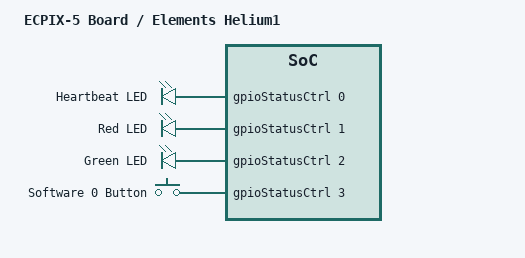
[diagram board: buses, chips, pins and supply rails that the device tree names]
/dts-v1/;
#include <elements/helium1.dtsi>

/ {
	model = "ECPIX-5 Board / Elements Helium1";
	compatible = "elements,ecpix5-helium1";

	chosen {
		zephyr,console = &uartStdCtrl;
		zephyr,shell-uart = &uartStdCtrl;
		zephyr,sram = &ram0;
	};

	gpio-leds {
		compatible = "gpio-leds";
		heartbeat: HEARTBEAT {
			gpios = <&gpioStatusCtrl 0 GPIO_ACTIVE_HIGH>;
			label = "Heartbeat LED";
		};

		red: RED {
			gpios = <&gpioStatusCtrl 1 GPIO_ACTIVE_HIGH>;
			label = "Red LED";
		};

		green: GREEN {
			gpios = <&gpioStatusCtrl 2 GPIO_ACTIVE_HIGH>;
			label = "Green LED";
		};
	};

	keys {
		compatible = "gpio-keys";
		sw0: SW0 {
			gpios = <&gpioStatusCtrl 3 GPIO_ACTIVE_HIGH>;
			label = "Software 0 Button";
		};
	};
};

&uartStdCtrl {
	clock-frequency = <100000000>;
};
